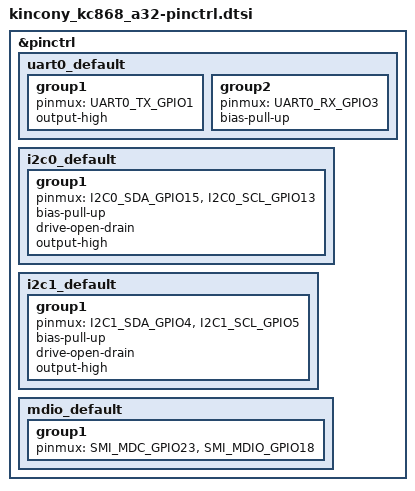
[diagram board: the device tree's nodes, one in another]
/*
 * Copyright (c) Bartosz Bilas
 *
 * SPDX-License-Identifier: Apache-2.0
 */

#include <zephyr/dt-bindings/pinctrl/esp-pinctrl-common.h>
#include <dt-bindings/pinctrl/esp32-pinctrl.h>
#include <zephyr/dt-bindings/pinctrl/esp32-gpio-sigmap.h>

&pinctrl {
	uart0_default: uart0_default {
		group1 {
			pinmux = <UART0_TX_GPIO1>;
			output-high;
		};
		group2 {
			pinmux = <UART0_RX_GPIO3>;
			bias-pull-up;
		};
	};

	i2c0_default: i2c0_default {
		group1 {
			pinmux = <I2C0_SDA_GPIO15>,
				 <I2C0_SCL_GPIO13>;
			bias-pull-up;
			drive-open-drain;
			output-high;
		};
	};

	i2c1_default: i2c1_default {
		group1 {
			pinmux = <I2C1_SDA_GPIO4>,
				 <I2C1_SCL_GPIO5>;
			bias-pull-up;
			drive-open-drain;
			output-high;
		};
	};

	mdio_default: mdio_default {
		group1 {
			pinmux = <SMI_MDC_GPIO23>,
				 <SMI_MDIO_GPIO18>;
		};
	};
};
